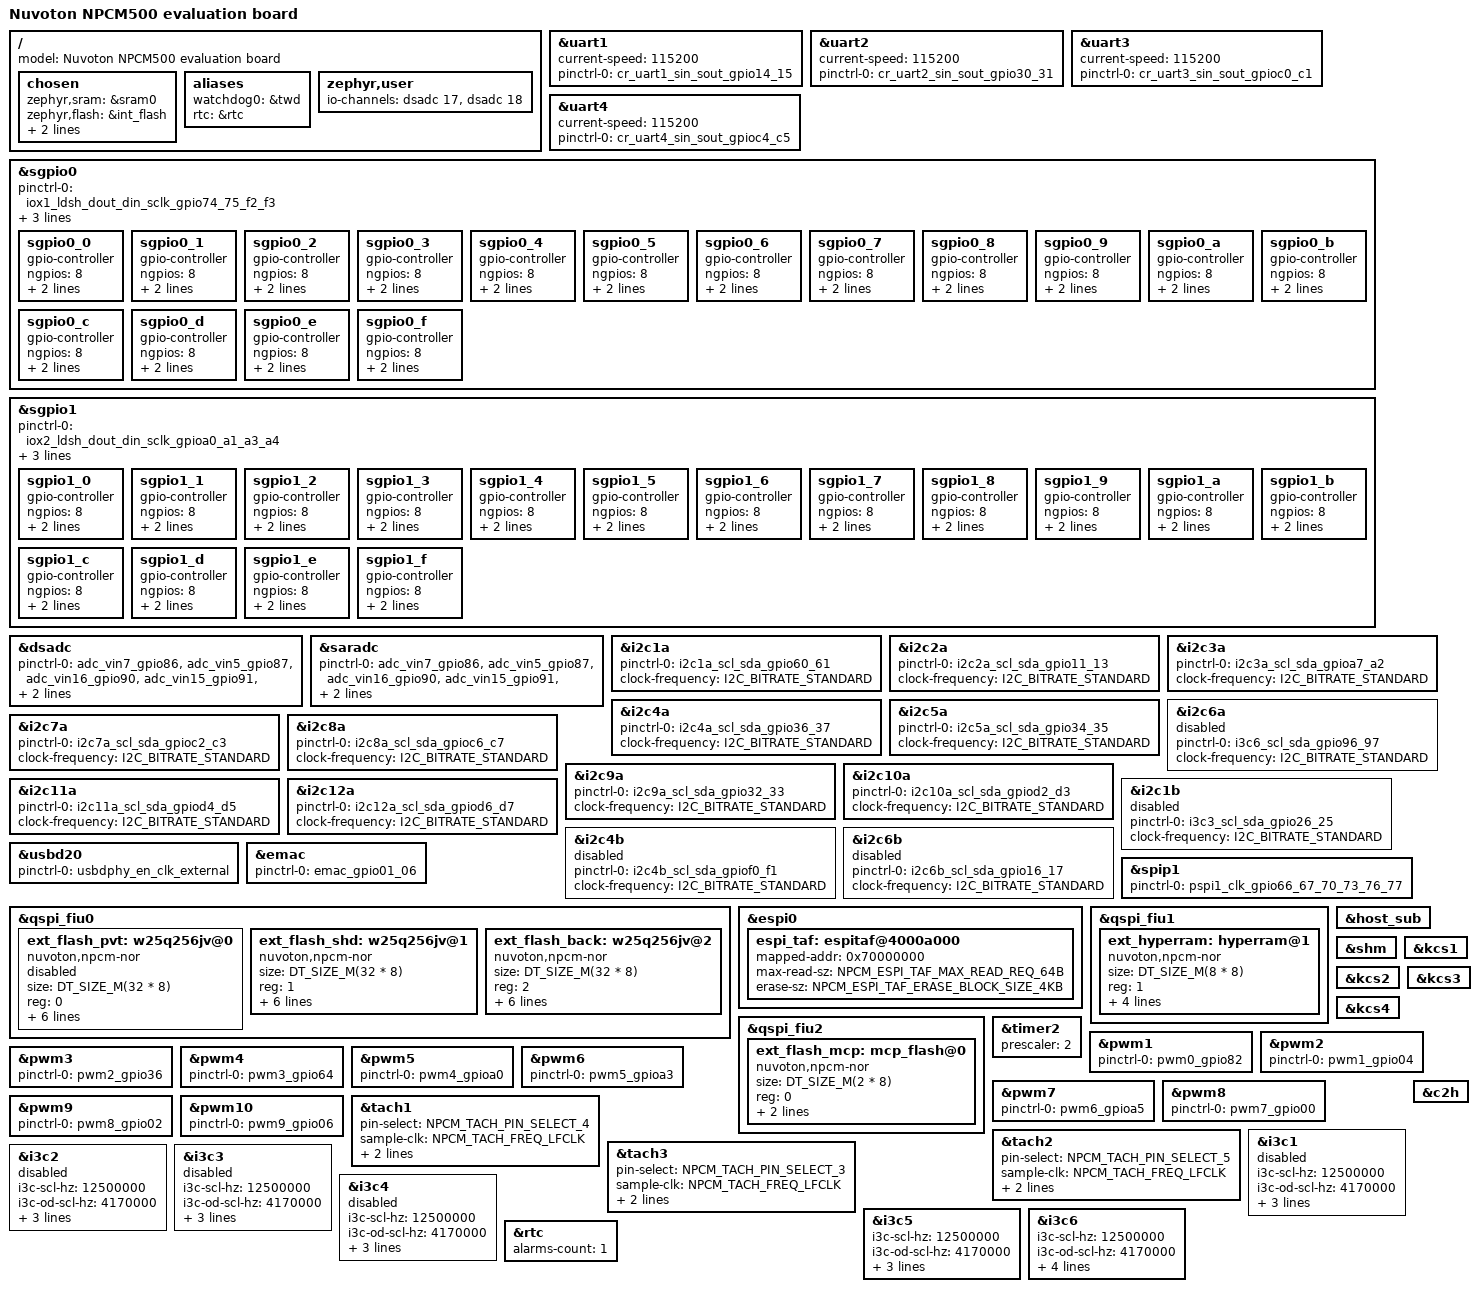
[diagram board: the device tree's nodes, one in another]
/*
 * Copyright (c) 2024 Nuvoton Technology Corporation.
 *
 * SPDX-License-Identifier: Apache-2.0
 */

/dts-v1/;

#include <nuvoton/npcm500.dtsi>
#include <nuvoton/npcm/npcm5/npcm5-pinctrl.dtsi>

/ {
	model = "Nuvoton NPCM500 evaluation board";

	chosen {
		zephyr,sram = &sram0;
		zephyr,flash = &int_flash;
		zephyr,shell-uart = &uart1;
		zephyr,console = &uart1;
	};

	aliases {
		watchdog0 = &twd;
		rtc = &rtc;
	};

	zephyr,user {
		/* adjust channel number according to enum adc_channel_en in adc_npcm.c */
		/* Because VIN16, THR16, TD2P is the same pin, it must only select one type.
		 * Because VIN15, THR15, TD0P is the same pin, it must only select one type.
		 * Because VIN14, THR14, TD1P is the same pin, it must only select one type.
		 * Because VIN1, THR1, TD3P is the same pin, it must only select one type.
		 * Because VIN2, THR2, TD4P is the same pin, it must only select one type.
		 * Exsample : if you select channel 6(VIN16),
		 *            and you can't select channel 7(THR16) and channel 19(TD2P).
		 */
		io-channels = <&dsadc 17>, <&dsadc 18>;
	};
};

&uart1 {
	status = "okay";
	current-speed = <115200>;
	pinctrl-0 = <&cr_uart1_sin_sout_gpio14_15>;
	pinctrl-names = "default";
};

&uart2 {
	status = "okay";
	current-speed = <115200>;
	pinctrl-0 = <&cr_uart2_sin_sout_gpio30_31>;
	pinctrl-names = "default";
};

&uart3 {
	status = "okay";
	current-speed = <115200>;
	pinctrl-0 = <&cr_uart3_sin_sout_gpioc0_c1>;
	pinctrl-names = "default";
};

&uart4 {
	status = "okay";
	current-speed = <115200>;
	pinctrl-0 = <&cr_uart4_sin_sout_gpioc4_c5>;
	pinctrl-names = "default";
};

&sgpio0 {
	status = "okay";
	pinctrl-0 = <&iox1_ldsh_dout_din_sclk_gpio74_75_f2_f3>;
	pinctrl-names = "default";
	nuvoton,input-ngpios = <64>;
	nuvoton,output-ngpios = <64>;
	nuvoton,bus-freq = <8000000>;
	sgpio0_0: sgpio0_0 {
		#gpio-cells = <2>;
		gpio-controller;
		ngpios = <8>;
		interrupt-controller;
		#interrupt-cells = <2>;
		pin-offset = <0>;
	};

	sgpio0_1: sgpio0_1 {
		#gpio-cells = <2>;
		gpio-controller;
		ngpios = <8>;
		interrupt-controller;
		#interrupt-cells = <2>;
		pin-offset = <8>;
	};

	sgpio0_2: sgpio0_2 {
		#gpio-cells = <2>;
		gpio-controller;
		ngpios = <8>;
		interrupt-controller;
		#interrupt-cells = <2>;
		pin-offset = <16>;
	};

	sgpio0_3: sgpio0_3 {
		#gpio-cells = <2>;
		gpio-controller;
		ngpios = <8>;
		interrupt-controller;
		#interrupt-cells = <2>;
		pin-offset = <24>;
	};

	sgpio0_4: sgpio0_4 {
		#gpio-cells = <2>;
		gpio-controller;
		ngpios = <8>;
		interrupt-controller;
		#interrupt-cells = <2>;
		pin-offset = <32>;
	};

	sgpio0_5: sgpio0_5 {
		#gpio-cells = <2>;
		gpio-controller;
		ngpios = <8>;
		interrupt-controller;
		#interrupt-cells = <2>;
		pin-offset = <40>;
	};

	sgpio0_6: sgpio0_6 {
		#gpio-cells = <2>;
		gpio-controller;
		ngpios = <8>;
		interrupt-controller;
		#interrupt-cells = <2>;
		pin-offset = <48>;
	};

	sgpio0_7: sgpio0_7 {
		#gpio-cells = <2>;
		gpio-controller;
		ngpios = <8>;
		interrupt-controller;
		#interrupt-cells = <2>;
		pin-offset = <56>;
	};

	sgpio0_8: sgpio0_8 {
		#gpio-cells = <2>;
		gpio-controller;
		ngpios = <8>;
		interrupt-controller;
		#interrupt-cells = <2>;
		pin-offset = <64>;
	};

	sgpio0_9: sgpio0_9 {
		#gpio-cells = <2>;
		gpio-controller;
		ngpios = <8>;
		interrupt-controller;
		#interrupt-cells = <2>;
		pin-offset = <72>;
	};

	sgpio0_a: sgpio0_a {
		#gpio-cells = <2>;
		gpio-controller;
		ngpios = <8>;
		interrupt-controller;
		#interrupt-cells = <2>;
		pin-offset = <80>;
	};

	sgpio0_b: sgpio0_b {
		#gpio-cells = <2>;
		gpio-controller;
		ngpios = <8>;
		interrupt-controller;
		#interrupt-cells = <2>;
		pin-offset = <88>;
	};

	sgpio0_c: sgpio0_c {
		#gpio-cells = <2>;
		gpio-controller;
		ngpios = <8>;
		interrupt-controller;
		#interrupt-cells = <2>;
		pin-offset = <96>;
	};

	sgpio0_d: sgpio0_d {
		#gpio-cells = <2>;
		gpio-controller;
		ngpios = <8>;
		interrupt-controller;
		#interrupt-cells = <2>;
		pin-offset = <104>;
	};

	sgpio0_e: sgpio0_e {
		#gpio-cells = <2>;
		gpio-controller;
		ngpios = <8>;
		interrupt-controller;
		#interrupt-cells = <2>;
		pin-offset = <112>;
	};

	sgpio0_f: sgpio0_f {
		#gpio-cells = <2>;
		gpio-controller;
		ngpios = <8>;
		interrupt-controller;
		#interrupt-cells = <2>;
		pin-offset = <120>;
	};
};

&sgpio1 {
	status = "okay";
	pinctrl-0 = <&iox2_ldsh_dout_din_sclk_gpioa0_a1_a3_a4>;
	pinctrl-names = "default";
	nuvoton,input-ngpios = <64>;
	nuvoton,output-ngpios = <64>;
	nuvoton,bus-freq = <8000000>;
	sgpio1_0: sgpio1_0 {
		#gpio-cells = <2>;
		gpio-controller;
		ngpios = <8>;
		interrupt-controller;
		#interrupt-cells = <2>;
		pin-offset = <0>;
	};

	sgpio1_1: sgpio1_1 {
		#gpio-cells = <2>;
		gpio-controller;
		ngpios = <8>;
		interrupt-controller;
		#interrupt-cells = <2>;
		pin-offset = <8>;
	};

	sgpio1_2: sgpio1_2 {
		#gpio-cells = <2>;
		gpio-controller;
		ngpios = <8>;
		interrupt-controller;
		#interrupt-cells = <2>;
		pin-offset = <16>;
	};

	sgpio1_3: sgpio1_3 {
		#gpio-cells = <2>;
		gpio-controller;
		ngpios = <8>;
		interrupt-controller;
		#interrupt-cells = <2>;
		pin-offset = <24>;
	};

	sgpio1_4: sgpio1_4 {
		#gpio-cells = <2>;
		gpio-controller;
		ngpios = <8>;
		interrupt-controller;
		#interrupt-cells = <2>;
		pin-offset = <32>;
	};

	sgpio1_5: sgpio1_5 {
		#gpio-cells = <2>;
		gpio-controller;
		ngpios = <8>;
		interrupt-controller;
		#interrupt-cells = <2>;
		pin-offset = <40>;
	};

	sgpio1_6: sgpio1_6 {
		#gpio-cells = <2>;
		gpio-controller;
		ngpios = <8>;
		interrupt-controller;
		#interrupt-cells = <2>;
		pin-offset = <48>;
	};

	sgpio1_7: sgpio1_7 {
		#gpio-cells = <2>;
		gpio-controller;
		ngpios = <8>;
		interrupt-controller;
		#interrupt-cells = <2>;
		pin-offset = <56>;
	};

	sgpio1_8: sgpio1_8 {
		#gpio-cells = <2>;
		gpio-controller;
		ngpios = <8>;
		interrupt-controller;
		#interrupt-cells = <2>;
		pin-offset = <64>;
	};

	sgpio1_9: sgpio1_9 {
		#gpio-cells = <2>;
		gpio-controller;
		ngpios = <8>;
		interrupt-controller;
		#interrupt-cells = <2>;
		pin-offset = <72>;
	};

	sgpio1_a: sgpio1_a {
		#gpio-cells = <2>;
		gpio-controller;
		ngpios = <8>;
		interrupt-controller;
		#interrupt-cells = <2>;
		pin-offset = <80>;
	};

	sgpio1_b: sgpio1_b {
		#gpio-cells = <2>;
		gpio-controller;
		ngpios = <8>;
		interrupt-controller;
		#interrupt-cells = <2>;
		pin-offset = <88>;
	};

	sgpio1_c: sgpio1_c {
		#gpio-cells = <2>;
		gpio-controller;
		ngpios = <8>;
		interrupt-controller;
		#interrupt-cells = <2>;
		pin-offset = <96>;
	};

	sgpio1_d: sgpio1_d {
		#gpio-cells = <2>;
		gpio-controller;
		ngpios = <8>;
		interrupt-controller;
		#interrupt-cells = <2>;
		pin-offset = <104>;
	};

	sgpio1_e: sgpio1_e {
		#gpio-cells = <2>;
		gpio-controller;
		ngpios = <8>;
		interrupt-controller;
		#interrupt-cells = <2>;
		pin-offset = <112>;
	};

	sgpio1_f: sgpio1_f {
		#gpio-cells = <2>;
		gpio-controller;
		ngpios = <8>;
		interrupt-controller;
		#interrupt-cells = <2>;
		pin-offset = <120>;
	};
};

&dsadc {
	status = "okay";
	/* Pin D7 is shared by thermal signal VIN16, THR16, TD2P.
	 * Pin C7 is shared by thermal signal VIN15, THR15, TD1P.
	 * Pin A6 is shared by thermal signal VIN14, THR14, TD0P.
	 * Pin B6 is shared by thermal signal VIN1, THR1, TD3P.
	 * Pin C6 is shared by thermal signal VIN2, THR2, TD4P.
	 */
	pinctrl-0 = <&adc_vin7_gpio86   /* VIN7 - C8 */
		     &adc_vin5_gpio87   /* VIN5 - F7 */
		     &adc_vin16_gpio90  /* VIN16/THR16/TD2P - D7 */
		     &adc_vin15_gpio91  /* VIN15/THR15/TD1P - C7 */
		     &adc_vin14_gpio92  /* VIN14/THR14/TD0P - A6 */
		     &adc_vin1_gpio93   /* VIN1/THR1/TD3P - B6 */
		     &adc_vin2_gpio94   /* VIN2/THR2/TD4P - C6 */
		     &adc_vin3_gpio95>; /* VIN3 - D6 */
	pinctrl-names = "default";
};

&saradc {
	status = "okay";
	pinctrl-0 = <&adc_vin7_gpio86   /* ADC Channel 0 - C8 */
		     &adc_vin5_gpio87   /* ADC Channel 1 - F7 */
		     &adc_vin16_gpio90  /* ADC Channel 2 - D7 */
		     &adc_vin15_gpio91  /* ADC Channel 3 - C7 */
		     &adc_vin14_gpio92  /* ADC Channel 4 - A6 */
		     &adc_vin1_gpio93   /* ADC Channel 5 - B6 */
		     &adc_vin2_gpio94   /* ADC Channel 6 - C6 */
		     &adc_vin3_gpio95>; /* ADC Channel 7 - D6 */
	pinctrl-names = "default";
};

&i2c1a {
	status = "okay";
	pinctrl-0 = <&i2c1a_scl_sda_gpio60_61>;
	pinctrl-names = "default";
	clock-frequency = <I2C_BITRATE_STANDARD>;
};

&i2c2a {
	status = "okay";
	pinctrl-0 = <&i2c2a_scl_sda_gpio11_13>;
	pinctrl-names = "default";
	clock-frequency = <I2C_BITRATE_STANDARD>;
};

&i2c3a {
	status = "okay";
	pinctrl-0 = <&i2c3a_scl_sda_gpioa7_a2>;
	pinctrl-names = "default";
	clock-frequency = <I2C_BITRATE_STANDARD>;
};

&i2c4a {
	status = "okay";
	pinctrl-0 = <&i2c4a_scl_sda_gpio36_37>;
	pinctrl-names = "default";
	clock-frequency = <I2C_BITRATE_STANDARD>;
};

&i2c5a {
	status = "okay";
	pinctrl-0 = <&i2c5a_scl_sda_gpio34_35>;
	pinctrl-names = "default";
	clock-frequency = <I2C_BITRATE_STANDARD>;
};

&i2c6a {
	status = "disabled";
	pinctrl-0 = <&i3c6_scl_sda_gpio96_97>;
	pinctrl-names = "default";
	clock-frequency = <I2C_BITRATE_STANDARD>;
};

&i2c7a {
	status = "okay";
	pinctrl-0 = <&i2c7a_scl_sda_gpioc2_c3>;
	pinctrl-names = "default";
	clock-frequency = <I2C_BITRATE_STANDARD>;
};

&i2c8a {
	status = "okay";
	pinctrl-0 = <&i2c8a_scl_sda_gpioc6_c7>;
	pinctrl-names = "default";
	clock-frequency = <I2C_BITRATE_STANDARD>;
};

&i2c9a {
	status = "okay";
	pinctrl-0 = <&i2c9a_scl_sda_gpio32_33>;
	pinctrl-names = "default";
	clock-frequency = <I2C_BITRATE_STANDARD>;
};

&i2c10a {
	status = "okay";
	pinctrl-0 = <&i2c10a_scl_sda_gpiod2_d3>;
	pinctrl-names = "default";
	clock-frequency = <I2C_BITRATE_STANDARD>;
};

&i2c11a {
	status = "okay";
	pinctrl-0 = <&i2c11a_scl_sda_gpiod4_d5>;
	pinctrl-names = "default";
	clock-frequency = <I2C_BITRATE_STANDARD>;
};

&i2c12a {
	status = "okay";
	pinctrl-0 = <&i2c12a_scl_sda_gpiod6_d7>;
	pinctrl-names = "default";
	clock-frequency = <I2C_BITRATE_STANDARD>;
};

&i2c1b {
	status = "disabled";
	pinctrl-0 = <&i3c3_scl_sda_gpio26_25>;
	pinctrl-names = "default";
	clock-frequency = <I2C_BITRATE_STANDARD>;
};

&i2c4b {
	status = "disabled";
	pinctrl-0 = <&i2c4b_scl_sda_gpiof0_f1>;
	pinctrl-names = "default";
	clock-frequency = <I2C_BITRATE_STANDARD>;
};

&i2c6b {
	status = "disabled";
	pinctrl-0 = <&i2c6b_scl_sda_gpio16_17>;
	pinctrl-names = "default";
	clock-frequency = <I2C_BITRATE_STANDARD>;
};

&usbd20 {
	status = "okay";
	pinctrl-0 = <&usbdphy_en_clk_external>;
	pinctrl-names = "default";
};

&emac {
	status = "okay";
	pinctrl-0 = <&emac_gpio01_06>;
	pinctrl-names = "default";
};

&spip1 {
	pinctrl-0 = <&pspi1_clk_gpio66_67_70_73_76_77>;
	pinctrl-names = "default";
	status = "okay";
};

&qspi_fiu0 {
	/*
	 * NPCM500 FIU0 chip select mapping (spec Table 4-1-1, UMA_ECTS):
	 *   SW_CS0 = PVT role  -> NO physical CS pin on FIU0 (only on FIU2)
	 *   SW_CS1 = SHD role  -> SHD_CS (GPIO44)  -> mapped 0xC000_0000
	 *   SW_CS2 = BACK role -> PVT_CS (GPIO23)  -> mapped 0xD000_0000
	 */
	ext_flash_pvt: w25q256jv@0 {
		compatible ="nuvoton,npcm-nor";
		size = <DT_SIZE_M(32 * 8)>;
		reg = <0>;
		enter-4byte-addr = <0xa5>;
		/* SW_CS0 has no physical CS on FIU0 - disabled on silicon */
		status = "disabled";

		qspi-flags = <NPCM_QSPI_SW_CS0>;
		mapped-addr = <0x60000000>;
		pinctrl-0 = <&fiu0_pvt_cs_io0_io1_clk_gpio23_45_46_47
			     &fiu0_shd_quad_io2_io3_clk_gpio55_56>;
		pinctrl-names = "default";
	};
	ext_flash_shd: w25q256jv@1 {
		compatible ="nuvoton,npcm-nor";
		size = <DT_SIZE_M(32 * 8)>;
		reg = <1>;
		enter-4byte-addr = <0xa5>;
		status = "okay";

		/* SHD role (SW_CS1): SHD_CS on GPIO44, AHB mapped at 0xC000_0000 */
		qspi-flags = <NPCM_QSPI_SW_CS1>;
		mapped-addr = <0xC0000000>;
		pinctrl-0 = <&fiu0_shd_cs_io0_io1_clk_gpio44_45_46_47
			     &fiu0_shd_quad_io2_io3_clk_gpio55_56>;
		pinctrl-names = "default";
	};
	ext_flash_back: w25q256jv@2 {
		compatible ="nuvoton,npcm-nor";
		size = <DT_SIZE_M(32 * 8)>;
		reg = <2>;
		enter-4byte-addr = <0xa5>;
		status = "okay";

		/* BACK role (SW_CS2): PVT flash uses PVT_CS on GPIO23, AHB mapped at 0xD000_0000 */
		qspi-flags = <NPCM_QSPI_SW_CS2>;
		mapped-addr = <0xD0000000>;
		pinctrl-0 = <&fiu0_pvt_cs_io0_io1_clk_gpio23_45_46_47
			     &fiu0_shd_quad_io2_io3_clk_gpio55_56>;
		pinctrl-names = "default";
	};
};

&espi0 {
	status = "okay";

	espi_taf: espitaf@4000a000 {
		mapped-addr = <0x70000000>;
		max-read-sz = "NPCM_ESPI_TAF_MAX_READ_REQ_64B";
		erase-sz = "NPCM_ESPI_TAF_ERASE_BLOCK_SIZE_4KB";
	};
};

/*
 * FIU1: On-chip QSPI pSRAM (Winbond W956D4NKR, 8MB MCP memory).
 * Register base 0x40022000, DRA mapped at 0x9000_0000.
 * Per NPCM500 spec §1.2: "optional on-chip 8-Mbyte HyperRAM" in MCP package.
 * Actual device is a standard QSPI pSRAM (SPI/QPI opcodes, not HyperBus).
 *
 * Access modes (per spec §4.1.7 hints #5-#8):
 *   - DRA (hints #5, #6): AHB reads/writes to 0x9000_0000.
 *     Requires BURST_CFG.SPI_WR_EN=1 for direct writes.
 *   - UMA (hints #7, #8): UMA register-based read/write.
 *   - JEDEC ID (0x9F) is supported (W956D4NKR datasheet §6.4).
 *   - Volatile memory (no erase required).
 */
&qspi_fiu1 {
	status = "okay";

	ext_hyperram: hyperram@1 {
		compatible = "nuvoton,npcm-nor";
		size = <DT_SIZE_M(8 * 8)>;
		reg = <1>;
		status = "okay";

		/* FIU1 SW_CS1 (SHD role) per chip-select table: HyperRAM */
		qspi-flags = <(NPCM_QSPI_SW_CS1 | NPCM_QSPI_QPI_MODE)>;
		mapped-addr = <0x90000000>;
		/*
		 * rd-mode QUAD: enables RESP_CFG.QUAD_EN for 4-wire data phase.
		 * Combined with NPCM_QSPI_QPI_MODE (Q_P_EN cmd+addr quad),
		 * this gives full QPI 4-4-4 mode for HyperRAM access.
		 */
		rd-mode = "NPCM_RD_MODE_QUAD";
	};
};

/*
 * FIU2: MCP internal flash (Winbond W25Q16JV, 2MB, 1.8V SPI NOR).
 * JEDEC ID: 0xEF 0x60 0x15 (Winbond, W25Q 1.8V, 2MB).
 * Register base 0x40023000, DRA mapped at 0xB000_0000.
 * Per spec §4.1: "FIU2 provides access to MCP flash devices."
 * Per spec device table: NPCM500MA has 2MB MCP flash.
 * Single-master (no host arbitration), uses SW_CS0 (PVT role).
 * 3-byte address only (capacity <= 16MB).
 * Internal MCP flash — no external GPIO pinctrl required.
 */
&qspi_fiu2 {
	status = "okay";

	ext_flash_mcp: mcp_flash@0 {
		compatible = "nuvoton,npcm-nor";
		size = <DT_SIZE_M(2 * 8)>;  /* 2MB = 16Mbit (W25Q16JV) */
		reg = <0>;
		status = "okay";

		/* PVT role (SW_CS0): MCP flash on FIU2, AHB mapped at 0xB000_0000 */
		qspi-flags = <NPCM_QSPI_SW_CS0>;
		mapped-addr = <0xB0000000>;
	};
};

&host_sub {
	status = "okay";
};

&shm{
	status = "okay";
};

&kcs1 {
	status = "okay";
};

&kcs2 {
	status = "okay";
};

&kcs3 {
	status = "okay";
};

&kcs4 {
	status = "okay";
};

&timer2 {
	prescaler = <2>;
	status = "okay";
};

&pwm1 {
	pinctrl-0 = <&pwm0_gpio82>;
	pinctrl-names = "default";
	status = "okay";
};

&pwm2 {
	pinctrl-0 = <&pwm1_gpio04>;
	pinctrl-names = "default";
	status = "okay";
};

&pwm3 {
	pinctrl-0 = <&pwm2_gpio36>;
	pinctrl-names = "default";
	status = "okay";
};

&pwm4 {
	pinctrl-0 = <&pwm3_gpio64>;
	pinctrl-names = "default";
	status = "okay";
};

&pwm5 {
	pinctrl-0 = <&pwm4_gpioa0>;
	pinctrl-names = "default";
	status = "okay";
};

&pwm6 {
	pinctrl-0 = <&pwm5_gpioa3>;
	pinctrl-names = "default";
	status = "okay";
};

&pwm7 {
	pinctrl-0 = <&pwm6_gpioa5>;
	pinctrl-names = "default";
	status = "okay";
};

&pwm8 {
	pinctrl-0 = <&pwm7_gpio00>;
	pinctrl-names = "default";
	status = "okay";
};

&pwm9 {
	pinctrl-0 = <&pwm8_gpio02>;
	pinctrl-names = "default";
	status = "okay";
};

&pwm10 {
	pinctrl-0 = <&pwm9_gpio06>;
	pinctrl-names = "default";
	status = "okay";
};

&tach1 {
	pin-select = <NPCM_TACH_PIN_SELECT_4>; /* Select tach pin 4 as input pin */
	sample-clk = <NPCM_TACH_FREQ_LFCLK>; /* Use LFCLK as sampling clock */
	pulses-per-round = <2>; /* number of pulses per round of encoder */
	pinctrl-0 = <&tach4_gpioa1>;
	pinctrl-names = "default";
	status = "okay";
};

&tach2 {
	pin-select = <NPCM_TACH_PIN_SELECT_5>; /* Select tach pin 5 as input pin */
	sample-clk = <NPCM_TACH_FREQ_LFCLK>; /* Use LFCLK as sampling clock */
	pulses-per-round = <2>; /* number of pulses per round of encoder */
	pinctrl-0 = <&tach5_gpioa4>;
	pinctrl-names = "default";
	status = "okay";
};

&tach3 {
	pin-select = <NPCM_TACH_PIN_SELECT_3>; /* Select tach pin 3 as input pin */
	sample-clk = <NPCM_TACH_FREQ_LFCLK>; /* Use LFCLK as sampling clock */
	pulses-per-round = <2>; /* number of pulses per round of encoder */
	pinctrl-0 = <&tach3_gpio81>;
	pinctrl-names = "default";
	status = "okay";
};

&i3c1 {
	i3c-scl-hz = <12500000>;
	i3c-od-scl-hz = <4170000>;
	i2c-scl-hz = <1000000>;
	pinctrl-0 = <&i3c1_scl_sda_gpio21_22>;
	bcr = <0x26>;
	pinctrl-names = "default";
	status = "disabled";
};

&i3c2 {
	i3c-scl-hz = <12500000>;
	i3c-od-scl-hz = <4170000>;
	i2c-scl-hz = <1000000>;
	pinctrl-0 = <&i3c2_scl_sda_gpio23_24>;
	bcr = <0x26>;
	pinctrl-names = "default";
	status = "disabled";
};

&i3c3 {
	i3c-scl-hz = <12500000>;
	i3c-od-scl-hz = <4170000>;
	i2c-scl-hz = <1000000>;
	pinctrl-0 = <&i3c3_scl_sda_gpio26_25>;
	bcr = <0x26>;
	pinctrl-names = "default";
	status = "disabled";
};

&i3c4 {
	i3c-scl-hz = <12500000>;
	i3c-od-scl-hz = <4170000>;
	i2c-scl-hz = <1000000>;
	pinctrl-0 = <&i3c4_scl_sda_gpiod0_d1>;
	bcr = <0x26>;
	pinctrl-names = "default";
	status = "disabled";
};

&i3c5 {
	i3c-scl-hz = <12500000>;
	i3c-od-scl-hz = <4170000>;
	i2c-scl-hz = <1000000>;
	pinctrl-0 = <&i3c5_scl_sda_gpio82_83>;
	bcr = <0x26>;
	pinctrl-names = "default";
	status = "okay";
};

&i3c6 {
	i3c-scl-hz = <12500000>;
	i3c-od-scl-hz = <4170000>;
	i2c-scl-hz = <1000000>;
	pinctrl-0 = <&i3c6_scl_sda_gpio96_97>;
	bcr = <0x26>;
	static-address = <0x50>;
	pinctrl-names = "default";
	status = "okay";
};

&c2h {
	status = "okay";
};

&rtc {
	alarms-count = <1>;
	status = "okay";
};
